AUTOSAR XML (schema 4-0-3)
package /ComponentTypes
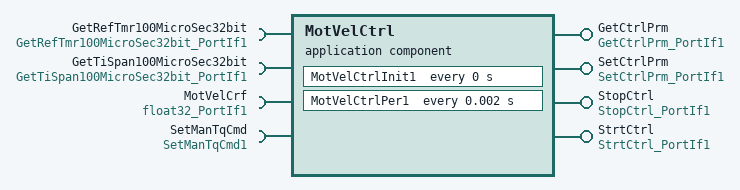
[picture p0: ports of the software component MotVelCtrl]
  application sw component type MotVelCtrl
    4 x provide port, all with server-com-spec{operation=Oper, queue-length=1}:
      GetCtrlPrm: provided-interface=GetCtrlPrm_PortIf1
      SetCtrlPrm: provided-interface=SetCtrlPrm_PortIf1
      StopCtrl: provided-interface=StopCtrl_PortIf1
      StrtCtrl: provided-interface=StrtCtrl_PortIf1
    4 x require port:
      GetRefTmr100MicroSec32bit: client-com-spec=Oper, required-interface=GetRefTmr100MicroSec32bit_PortIf1
      GetTiSpan100MicroSec32bit: client-com-spec=Oper, required-interface=GetTiSpan100MicroSec32bit_PortIf1
      MotVelCrf: nonqueued-receiver-com-spec{data-element=Val, filter=data-filter-type=ALWAYS, init-value=0}, required-interface=float32_PortIf1
      SetManTqCmd: client-com-spec=Oper, required-interface=SetManTqCmd1
    behavior MotVelCtrl_InternalBehavior: data-type-mapping=Nexteer
      ar-typed-per-instance-memorys:
        13 x data, all with sw-calibration-access=READ-ONLY:
          EnaCtrl: type=boolean
          EnaCtrlStVari: type=boolean
          FctActvSts: type=boolean
          MotVelTar: type=float32
          PrevAntiWdupCmd: type=float32
          PrevDerivtvOutp: type=float32
          PrevIntgtrInp: type=float32
          PrevIntgtrOutp: type=float32
          PrevMotVelErr: type=float32
          PrevMotVelTar: type=float32
          RampDwnCmpl: type=boolean
          RefTiRampDwn: type=uint32
          VelSlewRate: type=float32
      operation invoked event OIT_GetCtrlPrm_Oper_GetCtrlPrm_Oper: start-on-event=GetCtrlPrm_Oper, operation=GetCtrlPrm.Oper
      timing event MotVelCtrlInit1_InitEvent: start-on-event=MotVelCtrlInit1, period=0
      timing event TMT_MotVelCtrlPer1: start-on-event=MotVelCtrlPer1, period=0.002
      operation invoked event OIT_SetCtrlPrm_Oper_SetCtrlPrm_Oper: start-on-event=SetCtrlPrm_Oper, operation=SetCtrlPrm.Oper
      operation invoked event OIT_StopCtrl_Oper_StopCtrl_Oper: start-on-event=StopCtrl_Oper, operation=StopCtrl.Oper
      operation invoked event OIT_StrtCtrl_Oper_StrtCtrl_Oper: start-on-event=StrtCtrl_Oper, operation=StrtCtrl.Oper
      explicit-inter-runnable-variables:
        7 x data, all with type=float32:
          AntiWdupGain: init-value=1
          AntiWdupLim: init-value=5
          DerivtvGain: init-value=0.004
          DerivtvLpFilTiCon: init-value=0.008
          IntgtrGain: init-value=0.15
          PropGain: init-value=0.2
          TqCmdLim: init-value=8.8
      6 x runnable:
        GetCtrlPrm_Oper
          read-local-variables:
            7 x access:
              READ_AntiWdupGain: accessed-variable=AntiWdupGain
              READ_AntiWdupLim: accessed-variable=AntiWdupLim
              READ_DerivtvGain: accessed-variable=DerivtvGain
              READ_DerivtvLpFilTiCon: accessed-variable=DerivtvLpFilTiCon
              READ_IntgtrGain: accessed-variable=IntgtrGain
              READ_PropGain: accessed-variable=PropGain
              READ_TqCmdLim: accessed-variable=TqCmdLim
        MotVelCtrlInit1
        MotVelCtrlPer1
          data-receive-point-by-arguments:
            access REC_MotVelMrf_Val: accessed-variable=MotVelCrf.Val
          read-local-variables:
            7 x access:
              READ_AntiWdupGain: accessed-variable=AntiWdupGain
              READ_AntiWdupLim: accessed-variable=AntiWdupLim
              READ_DerivtvGain: accessed-variable=DerivtvGain
              READ_DerivtvLpFilTiCon: accessed-variable=DerivtvLpFilTiCon
              READ_IntgtrGain: accessed-variable=IntgtrGain
              READ_PropGain: accessed-variable=PropGain
              READ_TqCmdLim: accessed-variable=TqCmdLim
          sync call SC_GetRefTmr100MicroSec32bit_Oper: operation=GetRefTmr100MicroSec32bit.Oper, timeout=0
          sync call SC_GetTiSpan100MicroSec32bit_Oper: operation=GetTiSpan100MicroSec32bit.Oper, timeout=0
          sync call SC_SetManTqCmd_Oper: operation=SetManTqCmd.Oper, timeout=0
        SetCtrlPrm_Oper
          written-local-variables:
            7 x access:
              WRITE_AntiWdupGain: accessed-variable=AntiWdupGain
              WRITE_AntiWdupLim: accessed-variable=AntiWdupLim
              WRITE_DerivtvGain: accessed-variable=DerivtvGain
              WRITE_DerivtvLpFilTiCon: accessed-variable=DerivtvLpFilTiCon
              WRITE_IntgtrGain: accessed-variable=IntgtrGain
              WRITE_PropGain: accessed-variable=PropGain
              WRITE_TqCmdLim: accessed-variable=TqCmdLim
        StopCtrl_Oper
        StrtCtrl_Oper
  swc implementation MotVelCtrl_Implementation: behavior=MotVelCtrl_InternalBehavior
    code-descriptors:
      code Default: artifact-descriptors=autosar-engineering-object={short-label=Default, category=SWSRC}
